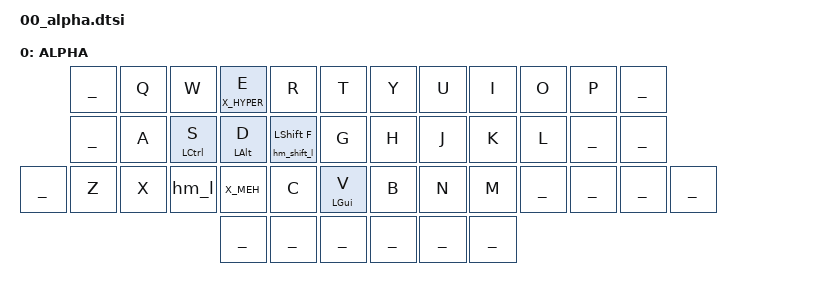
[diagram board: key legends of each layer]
/**
 * Alpha
 */
/ {
    keymap {
        compatible = "zmk,keymap";
            alpha {
                display-name = "ALPHA";
        bindings = <
// clang-format off
// ╭─────────────────────┬─────────────────────┬─────────────────────┬─────────────────────┬─────────────────────┬─────────────────────╮   ╭─────────────────────┬─────────────────────┬─────────────────────┬─────────────────────┬─────────────────────┬─────────────────────╮
// │0/LT5                │1/LT4                │2/LT3                │3/LT2                │4/LT1                │5/LT0                │   │6/RT0                │7/RT1                │8/RT2                │9/RT3                │10/RT4               │11/RT5               │
    ___                   &kp Q                 &kp W                 &hm_l X_HYPER E                &kp R                 &kp T                     &kp Y                 &kp U                 &kp I                 &kp O                 &kp P                 ___
// ├─────────────────────├─────────────────────┼─────────────────────┼─────────────────────┼─────────────────────┼─────────────────────┤   ├─────────────────────├─────────────────────┼─────────────────────┼─────────────────────┼─────────────────────┼─────────────────────┤
// │12/LM5               │13/LM4               │14/LM3               │15/LM2               │16/LM1               │17/LM0               │   │18/RM0               │19/RM1               │20/RM2               │21/RM3               │22/RM4               │23/RM5               │
    ___                   &kp A                 &hm_l LCTL S           &hm_l LALT D         &hm_shift_l LSHFT F   &kp G                     &kp H                 &kp J                 &kp K                 &kp L                 ___                   ___
// ├─────────────────────├─────────────────────┼─────────────────────┼─────────────────────┼─────────────────────┼─────────────────────┤   ├─────────────────────├─────────────────────┼─────────────────────┼─────────────────────┼─────────────────────┼─────────────────────┤
// │24/LB5               │25/LB4               │26/LB3               │27/LB2               │28/LB1               │29/LB0               │   │30/RB0               │31/RB1               │32/RB2               │33/RB3               │34/RB4               │35/RB5               │
    ___                   &kp Z                 &kp X                 &hm_l X_MEH C         &hm_l LGUI V         &kp B                     &kp N                 &kp M                 ___                   ___                   ___                   ___       
// ╰─────────────────────┴─────────────────────┴─────────────────────┼─────────────────────┼─────────────────────┼─────────────────────┤   ├─────────────────────├─────────────────────┼─────────────────────┼─────────────────────┴─────────────────────┴─────────────────────╯
//                                                                   │36/LH2               │37/LH1               │38/LH0               │   │39/RH0               │40/RH1               │41/RH2               │
                                                                      ___                   ___                   ___                       ___                   ___                   ___
//                                                                   ╰─────────────────────┴─────────────────────┴─────────────────────╯   ╰─────────────────────┴─────────────────────┴─────────────────────╯
      >;
    };
  };
};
